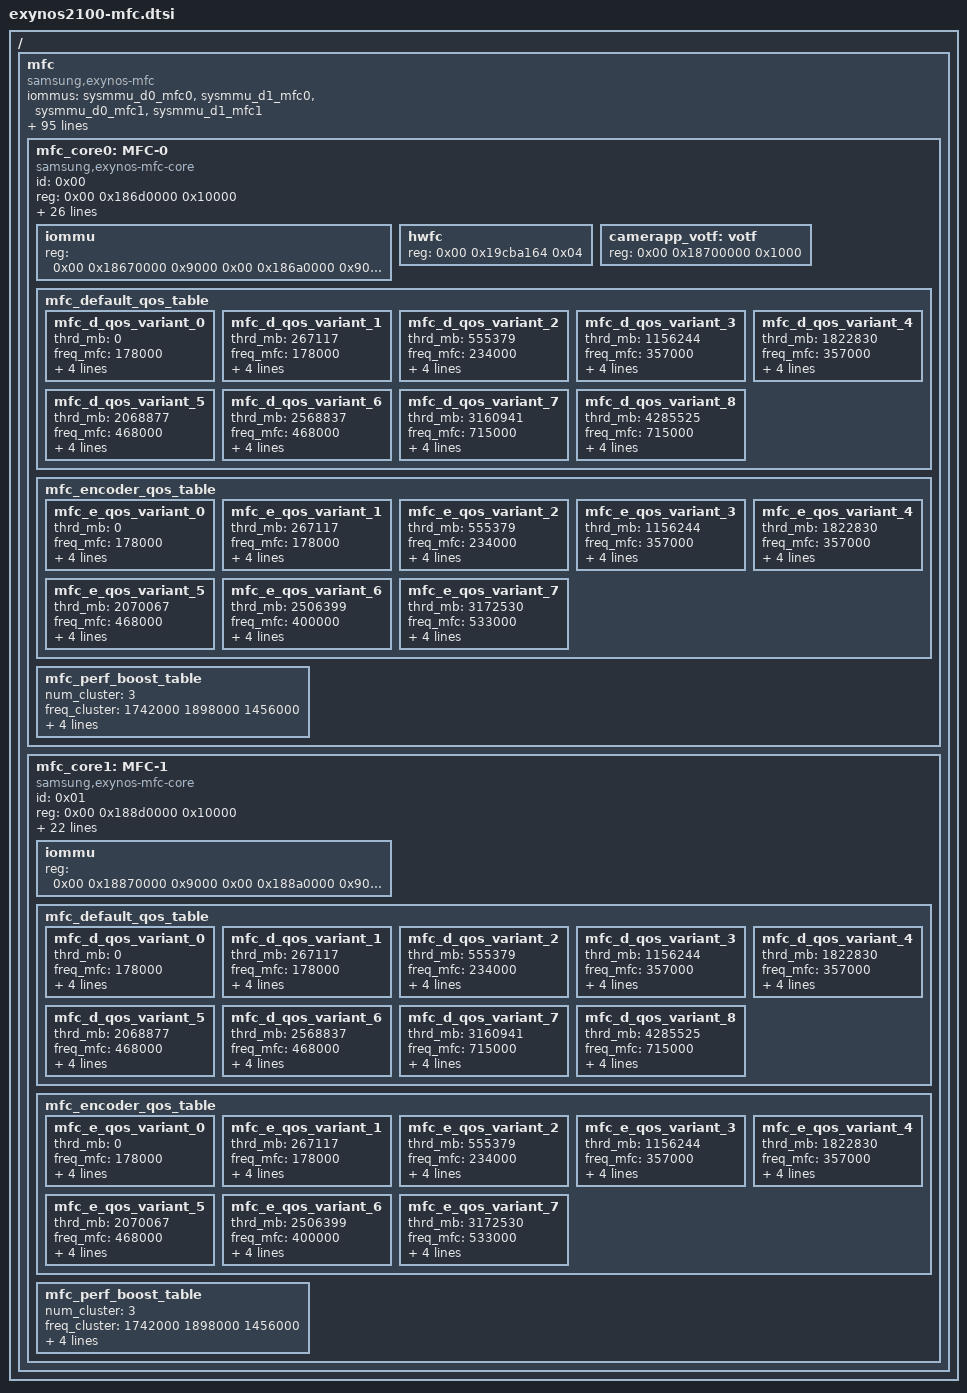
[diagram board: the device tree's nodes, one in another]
// SPDX-License-Identifier: GPL-2.0-only
/*
 * Exynos2100 SoC mfc device tree source
 *
 * Copyright (C) 2026 Samsung Electronics Co., Ltd.
 *		http://www.samsung.com
 *
 */

#include <dt-bindings/interrupt-controller/exynos2100.h>
#include <dt-bindings/clock/exynos2100.h>
#include <dt-bindings/soc/samsung/exynos_pm_qos.h>

/ {
	mfc: mfc {
		compatible = "samsung,exynos-mfc";
		iommus = <&sysmmu_d0_mfc0>, <&sysmmu_d1_mfc0>,
				<&sysmmu_d0_mfc1>, <&sysmmu_d1_mfc1>;
		samsung,iommu-group = <&iommu_group_mfc>;
		samsung,tzmp;

		/* MFC version */
		ip_ver = <0x1500010c>;
		debug_mode = <0>;
		nal_q_entry_size = <768>;
		nal_q_dump_size = <376>;
		nal_q = <0x01 0x00>;
		skype = <0x01 0x00>;
		black_bar = <0x01 0x00>;
		color_aspect_dec = <0x01 0x00>;
		static_info_dec = <0x01 0x00>;
		color_aspect_enc = <0x01 0x00>;
		static_info_enc = <0x01 0x180314>;
		hdr10_plus = <0x01 0x180709>;
		vp9_stride_align = <0x01 0x00>;
		sbwc_uncomp = <0x01 0x190702>;
		mem_clear = <0x01 0x00>;
		wait_fw_status = <0x01 0x190122>;
		wait_nalq_status = <0x01 0x191107>;
		drm_switch_predict = <0x01 0x00>;
		sbwc_enc_src_ctrl = <0x01 0x200110>;
		enc_idr_flag = <0x01 0x210614>;
		min_quality_mode = <0x01 0x210713>;
		support_av1_dec = <1>;
		av1_film_grain = <0x01 0x200717>;
		P010_decoding = <1>;
		dithering_enable = <0>;
		enc_ts_delta = <0x01 0x211015>;
		support_10bit = <1>;
		support_422 = <1>;
		support_rgb = <1>;
		support_sbwc = <1>;
		support_sbwcl = <1>;
		sbwc_dec_max_width = <1920>;
		sbwc_dec_max_height = <1088>;
		sbwc_dec_max_inst_num = <1>;
		max_hdr_win = <1>;
		display_err_type = <2>;
		display_framerate = <0>;
		enc_param_num = <25>;

		/* Encoder default parameter: max number is 100 */
		enc_param_addr = <
				0xf7b4 0xf7b8 0xf7b0 0xf798 0xfa2c
				0xf790 0xfa34 0xfa38 0xfa3c 0xf7c0
				0xf7c8 0xf7cc 0xfa60 0xfdd4 0xfddc
				0xfb54 0xfb58 0xfba8 0xfd90 0xfd94
				0xfd40 0xfd48 0xfd4c 0xfd50 0xfd80>;
		enc_param_val = <
				0x80 0x80 0x00 0x4000 0x3fd00
				0x00 0x00 0x2710 0x3e8 0x00
				0x00 0x00 0x00 0x8050d211 0x00
				0x3011 0x00 0x00 0x2d 0xa00
				0x1d 0xf4240 0x33003300 0x02 0x01>;

		/* BW <peak, read, write> : KB/UHD frame */
		bw_enc_h264 = <45456 56112 11170>;
		bw_enc_hevc = <46756 52766 9763>;
		bw_enc_hevc_10bit = <53865 64753 12556>;
		bw_enc_vp8 = <64000 67318 22518>;
		bw_enc_vp9 = <72326 59726 16530>;
		bw_enc_vp9_10bit = <149085 114928 31419>;
		bw_enc_mpeg4 = <44647 55324 9531>;
		bw_dec_h264 = <32605 34381 21263>;
		bw_dec_hevc = <29973 28851 17538>;
		bw_dec_hevc_10bit = <52859 46245 31351>;
		bw_dec_vp8 = <28672 30468 22324>;
		bw_dec_vp9 = <18351 18947 16877>;
		bw_dec_vp9_10bit = <42384 34452 31766>;
		bw_dec_av1 = <23787 19570 15856>;
		bw_dec_av1_10bit = <41407 35490 29699>;
		bw_dec_mpeg4 = <31540 25368 15770>;
		sbwc_bw_enc_h264 = <31622 32183 7065>;
		sbwc_bw_enc_hevc = <24044 27526 5888>;
		sbwc_bw_enc_hevc_10bit = <32666 37594 8841>;
		sbwc_bw_enc_vp8 = <32666 37594 8841>;
		sbwc_bw_enc_vp9 = <23276 26884 8702>;
		sbwc_bw_enc_vp9_10bit = <42302 41116 14052>;
		sbwc_bw_enc_mpeg4 = <32666 37594 8841>;
		sbwc_bw_dec_h264 = <23757 18603 13620>;
		sbwc_bw_dec_hevc = <15309 15387 10279>;
		sbwc_bw_dec_hevc_10bit = <20808 20602 14868>;
		sbwc_bw_dec_vp8 = <17203 18281 13394>;
		sbwc_bw_dec_vp9 = <11121 9691 8999>;
		sbwc_bw_dec_vp9_10bit = <17787 15582 14413>;
		sbwc_bw_dec_mpeg4 = <18924 15221 9462>;
		num_mfc_freq = <7>;
		mfc_freqs = <
				178000 234000 357000 468000
				533000 663000 715000>;
		max_Kbps = <245760 81920>;
		qos_weight_h264_hevc = <100>;
		qos_weight_vp8_vp9 = <100>;
		qos_weight_av1 = <70>;
		qos_weight_other_codec = <25>;
		qos_weight_3plane = <80>;
		qos_weight_10bit = <75>;
		qos_weight_422 = <70>;
		qos_weight_bframe = <50>;
		qos_weight_num_of_ref = <60>;
		qos_weight_gpb = <50>;
		qos_weight_num_of_tile = <75>;
		qos_weight_super64_bframe = <60>;
		qos_weight_mbaff = <60>;
		core_balance = <54>;
		iova_threshold = <1700>;
		idle_clk_ctrl = <1>;
		enc_timing_dis = <0x01>;
		#address-cells = <2>;
		#size-cells = <1>;
		ranges;

		mfc_core0: MFC-0 {
			compatible = "samsung,exynos-mfc-core";
			id = <0x00>;
			reg = <0x00 0x186d0000 0x10000>;
			interrupts = <GIC_SPI INTREQ__MFC0 IRQ_TYPE_LEVEL_HIGH>;
			clock-names = "aclk_mfc";
			clocks = <&clock UMUX_CLKCMU_MFC0_MFC0>;
			iommus = <&sysmmu_d0_mfc0>, <&sysmmu_d1_mfc0>;
			samsung,iommu-group = <&iommu_group_mfc>;
			samsung,tzmp;
			samsung,imgloader-s2mpu-support;

			/* MFC version */
			ip_ver = <0x1500010c>;

			/* Sysmmu check */
			share_sysmmu = <0>;
			axid_mask = <0xffff>;
			mfc_fault_num = <0x00>;
			trans_info_offset = <0x1004>;

			/* LLC (Last Level Cache) */
			llc = <1>;
			need_llc_flush = <0>;

			/* vOTF */
			mfc_votf_base = <0x18700000>;
			gdc_votf_base = <0x15e10000>;
			votf_start_offset = <0xf000>;
			votf_end_offset = <0x10000>;
			num_default_qos_steps = <9>;
			num_encoder_qos_steps = <8>;
			max_mb = <5315425>;
			max_hw_mb = <3888000>;
			mfc_freq_control = <1>;
			mo_control = <1>;
			bw_control = <1>;
			#dma-address-cells = <1>;
			#dma-size-cells = <1>;
			dma-window = <0x00 0xd0000000>;
			#address-cells = <2>;
			#size-cells = <1>;
			ranges;

			iommu { reg = <0x00 0x18670000 0x9000 0x00 0x186a0000 0x9000>; };
			hwfc { reg = <0x00 0x19cba164 0x04>; };
			camerapp_votf: votf { reg = <0x00 0x18700000 0x1000>; };

			/* Default QoS table */
			mfc_default_qos_table {
				mfc_d_qos_variant_0 {
					thrd_mb = <0>;
					freq_mfc = <178000>;
					freq_int = <80000>;
					freq_mif = <421000>;
					time_fw = <1474>;
					bts_scen = "default";
				};
				mfc_d_qos_variant_1 {
					thrd_mb = <267117>;
					freq_mfc = <178000>;
					freq_int = <80000>;
					freq_mif = <421000>;
					time_fw = <1474>;
					bts_scen = "default";
				};
				mfc_d_qos_variant_2 {
					thrd_mb = <555379>;
					freq_mfc = <234000>;
					freq_int = <267000>;
					freq_mif = <676000>;
					time_fw = <776>;
					bts_scen = "default";
				};
				mfc_d_qos_variant_3 {
					thrd_mb = <1156244>;
					freq_mfc = <357000>;
					freq_int = <267000>;
					freq_mif = <1014000>;
					time_fw = <579>;
					bts_scen = "default";
				};
				mfc_d_qos_variant_4 {
					thrd_mb = <1822830>;
					freq_mfc = <357000>;
					freq_int = <400000>;
					freq_mif = <1014000>;
					time_fw = <506>;
					bts_scen = "default";
				};
				mfc_d_qos_variant_5 {
					thrd_mb = <2068877>;
					freq_mfc = <468000>;
					freq_int = <400000>;
					freq_mif = <1352000>;
					time_fw = <411>;
					bts_scen = "mfc_uhd";
				};
				mfc_d_qos_variant_6 {
					thrd_mb = <2568837>;
					freq_mfc = <468000>;
					freq_int = <533000>;
					freq_mif = <2288000>;
					time_fw = <361>;
					bts_scen = "mfc_uhd";
				};
				mfc_d_qos_variant_7 {
					thrd_mb = <3160941>;
					freq_mfc = <715000>;
					freq_int = <533000>;
					freq_mif = <2535000>;
					time_fw = <273>;
					bts_scen = "mfc_uhd";
				};
				mfc_d_qos_variant_8 {
					thrd_mb = <4285525>;
					freq_mfc = <715000>;
					freq_int = <800000>;
					freq_mif = <2730000>;
					time_fw = <228>;
					bts_scen = "mfc_uhd_10bit";
				};
			};

			mfc_encoder_qos_table {
				mfc_e_qos_variant_0 {
					thrd_mb = <0>;
					freq_mfc = <178000>;
					freq_int = <80000>;
					freq_mif = <421000>;
					time_fw = <1474>;
					bts_scen = "default";
				};
				mfc_e_qos_variant_1 {
					thrd_mb = <267117>;
					freq_mfc = <178000>;
					freq_int = <80000>;
					freq_mif = <421000>;
					time_fw = <1474>;
					bts_scen = "default";
				};
				mfc_e_qos_variant_2 {
					thrd_mb = <555379>;
					freq_mfc = <234000>;
					freq_int = <267000>;
					freq_mif = <676000>;
					time_fw = <776>;
					bts_scen = "default";
				};
				mfc_e_qos_variant_3 {
					thrd_mb = <1156244>;
					freq_mfc = <357000>;
					freq_int = <267000>;
					freq_mif = <1014000>;
					time_fw = <579>;
					bts_scen = "default";
				};
				mfc_e_qos_variant_4 {
					thrd_mb = <1822830>;
					freq_mfc = <357000>;
					freq_int = <267000>;
					freq_mif = <1352000>;
					time_fw = <515>;
					bts_scen = "default";
				};
				mfc_e_qos_variant_5 {
					thrd_mb = <2070067>;
					freq_mfc = <468000>;
					freq_int = <400000>;
					freq_mif = <1352000>;
					time_fw = <411>;
					bts_scen = "mfc_uhd";
				};
				mfc_e_qos_variant_6 {
					thrd_mb = <2506399>;
					freq_mfc = <400000>;
					freq_int = <400000>;
					freq_mif = <1539000>;
					time_fw = <361>;
					bts_scen = "mfc_uhd";
				};
				mfc_e_qos_variant_7 {
					thrd_mb = <3172530>;
					freq_mfc = <533000>;
					freq_int = <533000>;
					freq_mif = <2028000>;
					time_fw = <296>;
					bts_scen = "mfc_uhd";
				};
			};

			mfc_perf_boost_table {
				num_cluster = <3>;
				freq_cluster = <1742000 1898000 1456000>;
				freq_mfc = <666000>;
				freq_int = <534000>;
				freq_mif = <2730000>;
				bts_scen = "mfc_uhd_10bit";
			};
		};

		mfc_core1: MFC-1 {
			compatible = "samsung,exynos-mfc-core";
			id = <0x01>;
			reg = <0x00 0x188d0000 0x10000>;
			interrupts = <GIC_SPI INTREQ__MFC1 IRQ_TYPE_LEVEL_HIGH>;
			clock-names = "aclk_mfc";
			clocks = <&clock GATE_ADM_APB_MFC0MFC1_QCH>;
			iommus = <&sysmmu_d0_mfc1>, <&sysmmu_d1_mfc1>;
			samsung,iommu-group = <&iommu_group_mfc>;
			samsung,tzmp;
			samsung,imgloader-s2mpu-support;

			/* MFC version */
			ip_ver = <0x1500010d>;

			/* Sysmmu check */
			share_sysmmu = <0>;
			axid_mask = <0xffff>;
			mfc_fault_num = <0x00>;
			trans_info_offset = <0x1004>;

			/* LLC (Last Level Cache) */
			llc = <1>;
			need_llc_flush = <0>;
			num_default_qos_steps = <9>;
			num_encoder_qos_steps = <8>;
			max_mb = <5315425>;
			max_hw_mb = <3888000>;
			mfc_freq_control = <1>;
			mo_control = <1>;
			bw_control = <1>;
			#dma-address-cells = <1>;
			#dma-size-cells = <1>;
			dma-window = <0x00 0xd0000000>;
			#address-cells = <2>;
			#size-cells = <1>;
			ranges;

			iommu { reg = <0x00 0x18870000 0x9000 0x00 0x188a0000 0x9000>; };

			/* Default QoS table */
			mfc_default_qos_table {
				mfc_d_qos_variant_0 {
					thrd_mb = <0>;
					freq_mfc = <178000>;
					freq_int = <80000>;
					freq_mif = <421000>;
					time_fw = <1474>;
					bts_scen = "default";
				};
				mfc_d_qos_variant_1 {
					thrd_mb = <267117>;
					freq_mfc = <178000>;
					freq_int = <80000>;
					freq_mif = <421000>;
					time_fw = <1474>;
					bts_scen = "default";
				};
				mfc_d_qos_variant_2 {
					thrd_mb = <555379>;
					freq_mfc = <234000>;
					freq_int = <267000>;
					freq_mif = <676000>;
					time_fw = <776>;
					bts_scen = "default";
				};
				mfc_d_qos_variant_3 {
					thrd_mb = <1156244>;
					freq_mfc = <357000>;
					freq_int = <267000>;
					freq_mif = <1014000>;
					time_fw = <579>;
					bts_scen = "default";
				};
				mfc_d_qos_variant_4 {
					thrd_mb = <1822830>;
					freq_mfc = <357000>;
					freq_int = <400000>;
					freq_mif = <1014000>;
					time_fw = <506>;
					bts_scen = "default";
				};
				mfc_d_qos_variant_5 {
					thrd_mb = <2068877>;
					freq_mfc = <468000>;
					freq_int = <400000>;
					freq_mif = <1352000>;
					time_fw = <411>;
					bts_scen = "mfc_uhd";
				};
				mfc_d_qos_variant_6 {
					thrd_mb = <2568837>;
					freq_mfc = <468000>;
					freq_int = <533000>;
					freq_mif = <2288000>;
					time_fw = <361>;
					bts_scen = "mfc_uhd";
				};
				mfc_d_qos_variant_7 {
					thrd_mb = <3160941>;
					freq_mfc = <715000>;
					freq_int = <533000>;
					freq_mif = <2535000>;
					time_fw = <273>;
					bts_scen = "mfc_uhd";
				};
				mfc_d_qos_variant_8 {
					thrd_mb = <4285525>;
					freq_mfc = <715000>;
					freq_int = <800000>;
					freq_mif = <2730000>;
					time_fw = <228>;
					bts_scen = "mfc_uhd_10bit";
				};
			};

			mfc_encoder_qos_table {
				mfc_e_qos_variant_0 {
					thrd_mb = <0>;
					freq_mfc = <178000>;
					freq_int = <80000>;
					freq_mif = <421000>;
					time_fw = <1474>;
					bts_scen = "default";
				};
				mfc_e_qos_variant_1 {
					thrd_mb = <267117>;
					freq_mfc = <178000>;
					freq_int = <80000>;
					freq_mif = <421000>;
					time_fw = <1474>;
					bts_scen = "default";
				};
				mfc_e_qos_variant_2 {
					thrd_mb = <555379>;
					freq_mfc = <234000>;
					freq_int = <267000>;
					freq_mif = <676000>;
					time_fw = <776>;
					bts_scen = "default";
				};
				mfc_e_qos_variant_3 {
					thrd_mb = <1156244>;
					freq_mfc = <357000>;
					freq_int = <267000>;
					freq_mif = <1014000>;
					time_fw = <579>;
					bts_scen = "default";
				};
				mfc_e_qos_variant_4 {
					thrd_mb = <1822830>;
					freq_mfc = <357000>;
					freq_int = <267000>;
					freq_mif = <1352000>;
					time_fw = <515>;
					bts_scen = "default";
				};
				mfc_e_qos_variant_5 {
					thrd_mb = <2070067>;
					freq_mfc = <468000>;
					freq_int = <400000>;
					freq_mif = <1352000>;
					time_fw = <411>;
					bts_scen = "mfc_uhd";
				};
				mfc_e_qos_variant_6 {
					thrd_mb = <2506399>;
					freq_mfc = <400000>;
					freq_int = <400000>;
					freq_mif = <1539000>;
					time_fw = <361>;
					bts_scen = "mfc_uhd";
				};
				mfc_e_qos_variant_7 {
					thrd_mb = <3172530>;
					freq_mfc = <533000>;
					freq_int = <533000>;
					freq_mif = <2028000>;
					time_fw = <296>;
					bts_scen = "mfc_uhd";
				};
			};

			/* QoS table for performance boost mode */
			mfc_perf_boost_table {
				num_cluster = <3>;
				freq_cluster = <1742000 1898000 1456000>;
				freq_mfc = <666000>;
				freq_int = <534000>;
				freq_mif = <2730000>;
				bts_scen = "mfc_uhd_10bit";
			};
		};
	};
};
